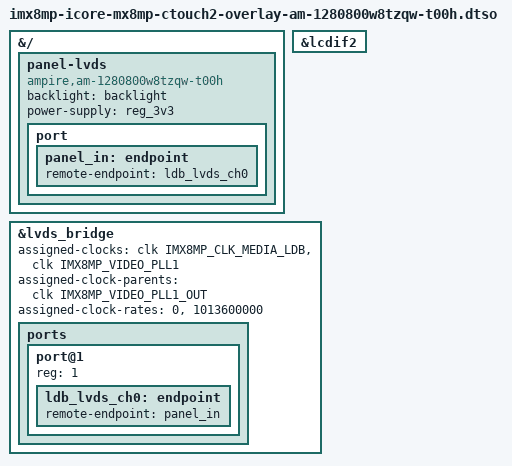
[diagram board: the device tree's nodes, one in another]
// SPDX-License-Identifier: (GPL-2.0+ OR MIT)
/*
 * Copyright (C) 2026 Amarula Solutions, Dario Binacchi <dario.binacchi@amarulasolutions.com>
 * Copyright (C) 2026 Engicam srl
 *
 * Ampire AM-1280800W8TZQW-T00H 10.1" 1280x800 LVDS panel. Its touchscreen
 * controller is connected over USB.
 */

/dts-v1/;
/plugin/;

#include <dt-bindings/clock/imx8mp-clock.h>

&{/} {
	panel-lvds {
		compatible = "ampire,am-1280800w8tzqw-t00h";
		backlight = <&backlight>;
		power-supply = <&reg_3v3>;

		port {
			panel_in: endpoint {
				remote-endpoint = <&ldb_lvds_ch0>;
			};
		};
	};
};

&lcdif2 {
	status = "okay";
};

&lvds_bridge {
	assigned-clocks = <&clk IMX8MP_CLK_MEDIA_LDB>,
			  <&clk IMX8MP_VIDEO_PLL1>;
	assigned-clock-parents = <&clk IMX8MP_VIDEO_PLL1_OUT>;
	/* IMX8MP_VIDEO_PLL1 = IMX8MP_CLK_MEDIA_DISP2_PIX * 2 * 7 */
	assigned-clock-rates = <0>, <1013600000>;
	status = "okay";

	ports {
		#address-cells = <1>;
		#size-cells = <0>;

		port@1 {
			reg = <1>;

			ldb_lvds_ch0: endpoint {
				remote-endpoint = <&panel_in>;
			};
		};
	};
};
